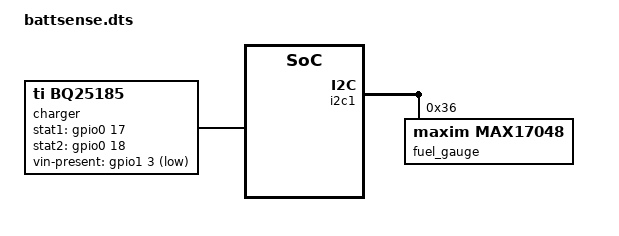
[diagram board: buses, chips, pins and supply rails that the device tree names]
#include <zephyr/dt-bindings/input/input-event-codes.h>

/ {
	zephyr,user {

		ykb-battsense-charger = <&charger>;
		ykb-battsense-fuel-gauge = <&fuel_gauge>;
	};

	charger: charger {
		compatible = "ti,bq25185";
		stat1-gpios = <&gpio0 17 GPIO_ACTIVE_HIGH>;
		stat2-gpios = <&gpio0 18 GPIO_ACTIVE_HIGH>;
		vin-present-gpios = <&gpio1 3 GPIO_ACTIVE_LOW>;
		status = "okay";
	};
};

&i2c1 {
	fuel_gauge: fuel_gauge@36 {
		compatible = "maxim,max17048";
		status = "okay";
		reg = <0x36>;
	};
};
